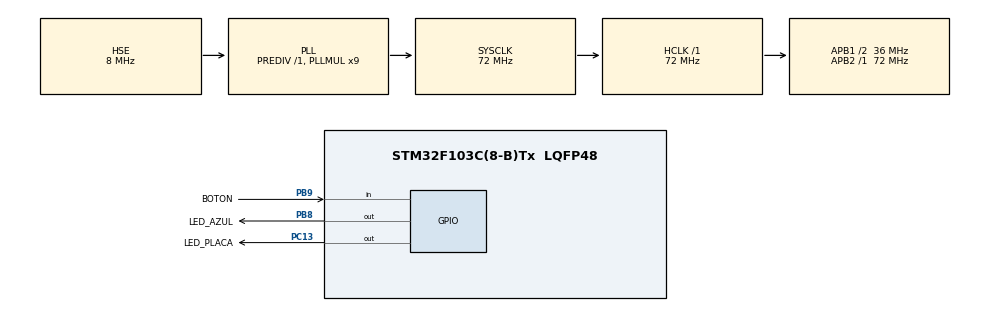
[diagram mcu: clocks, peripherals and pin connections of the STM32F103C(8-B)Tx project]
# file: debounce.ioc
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Mcu.Family=STM32F1
Mcu.Name=STM32F103C(8-B)Tx
Mcu.Package=LQFP48
NVIC.PriorityGroup=NVIC_PRIORITYGROUP_4
PA13.Mode=Serial_Wire
PA13.Signal=SYS_JTMS-SWDIO
PA14.Mode=Serial_Wire
PA14.Signal=SYS_JTCK-SWCLK
PB8.GPIO_Label=LED_AZUL
PB8.Signal=GPIO_Output
PB9.GPIO_Label=BOTON
PB9.GPIO_PuPd=GPIO_PULLUP
PB9.Signal=GPIO_Input
PC13-TAMPER-RTC.GPIO_Label=LED_PLACA
PC13-TAMPER-RTC.Signal=GPIO_Output
PD0-OSC_IN.Mode=HSE-External-Oscillator
PD0-OSC_IN.Signal=RCC_OSC_IN
PD1-OSC_OUT.Mode=HSE-External-Oscillator
PD1-OSC_OUT.Signal=RCC_OSC_OUT
ProjectManager.HeapSize=0x200
ProjectManager.StackSize=0x400
ProjectManager.TargetToolchain=STM32CubeIDE
RCC.AHBFreq_Value=72000000
RCC.APB1CLKDivider=RCC_HCLK_DIV2
RCC.APB1Freq_Value=36000000
RCC.APB1TimFreq_Value=72000000
RCC.APB2Freq_Value=72000000
RCC.APB2TimFreq_Value=72000000
RCC.HCLKFreq_Value=72000000
RCC.PLLMUL=RCC_PLL_MUL9
RCC.PLLSourceVirtual=RCC_PLLSOURCE_HSE
RCC.SYSCLKFreq_VALUE=72000000
RCC.SYSCLKSource=RCC_SYSCLKSOURCE_PLLCLK
RCC.USBFreq_Value=72000000
board=custom

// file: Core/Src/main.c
/* USER CODE BEGIN Header */
/**
  ******************************************************************************
  * @file           : main.c
  * @brief          : Main program body
  ******************************************************************************
  * @attention
  *
  * Copyright (c) 2022 STMicroelectronics.
  * All rights reserved.
  *
  * This software is licensed under terms that can be found in the LICENSE file
  * in the root directory of this software component.
  * If no LICENSE file comes with this software, it is provided AS-IS.
  *
  ******************************************************************************
  */
/* USER CODE END Header */
#include "main.h"

/* USER CODE BEGIN Includes */
#include "arrebote.h"
/* USER CODE END Includes */

/* USER CODE BEGIN PD */
#define TIC_LED					(125)
#define TIC_ANTIRREBOTE			(1)
#define PULSADOR_DEBOUNCE		(20)
#define PULSADOR_ESTADO_ACTIVO	(1)
/* USER CODE END PD */

void SystemClock_Config(void);
static void MX_GPIO_Init(void);

int main(void)
{
  /* USER CODE BEGIN 1 */
	uint32_t tics_led;
	uint32_t tics_antirrebote;
	arrebote debounce_pulsador;
  /* USER CODE END 1 */

  /* MCU Configuration--------------------------------------------------------*/

  /* Reset of all peripherals, Initializes the Flash interface and the Systick. */
  HAL_Init();

  /* Configure the system clock */
  SystemClock_Config();

  /* Initialize all configured peripherals */
  MX_GPIO_Init();
  /* USER CODE BEGIN 2 */
  inicializar_arrebote(&debounce_pulsador, PULSADOR_ESTADO_ACTIVO, PULSADOR_DEBOUNCE);
  tics_led = HAL_GetTick();
  tics_antirrebote = HAL_GetTick();

  /* USER CODE END 2 */

  /* Infinite loop */
  while (1)
  {

    /* USER CODE BEGIN 3 */
	  if((HAL_GetTick()-tics_led)>=TIC_LED)
	  {
		  tics_led = HAL_GetTick();
		  HAL_GPIO_TogglePin(LED_PLACA_GPIO_Port, LED_PLACA_Pin);

	  }

	  if((HAL_GetTick()-tics_antirrebote)>=TIC_ANTIRREBOTE)
	  	  {
	  		  tics_antirrebote = HAL_GetTick();
	  		  chequear_arrebote(&debounce_pulsador, HAL_GPIO_ReadPin(BOTON_GPIO_Port, BOTON_Pin));
	  		  if(hay_flanco_arrebote(&debounce_pulsador))
	  		  {
	  			  HAL_GPIO_TogglePin(LED_AZUL_GPIO_Port, LED_AZUL_Pin);
	  		  }
	  	  }

  }
  /* USER CODE END 3 */
}

void SystemClock_Config(void)
{
  RCC_OscInitTypeDef RCC_OscInitStruct = {0};
  RCC_ClkInitTypeDef RCC_ClkInitStruct = {0};

  /** Initializes the RCC Oscillators according to the specified parameters
  * in the RCC_OscInitTypeDef structure.
  */
  RCC_OscInitStruct.OscillatorType = RCC_OSCILLATORTYPE_HSE;
  RCC_OscInitStruct.HSEState = RCC_HSE_ON;
  RCC_OscInitStruct.HSEPredivValue = RCC_HSE_PREDIV_DIV1;
  RCC_OscInitStruct.HSIState = RCC_HSI_ON;
  RCC_OscInitStruct.PLL.PLLState = RCC_PLL_ON;
  RCC_OscInitStruct.PLL.PLLSource = RCC_PLLSOURCE_HSE;
  RCC_OscInitStruct.PLL.PLLMUL = RCC_PLL_MUL9;
  if (HAL_RCC_OscConfig(&RCC_OscInitStruct) != HAL_OK)
  {
    Error_Handler();
  }
  /** Initializes the CPU, AHB and APB buses clocks
  */
  RCC_ClkInitStruct.ClockType = RCC_CLOCKTYPE_HCLK|RCC_CLOCKTYPE_SYSCLK
                              |RCC_CLOCKTYPE_PCLK1|RCC_CLOCKTYPE_PCLK2;
  RCC_ClkInitStruct.SYSCLKSource = RCC_SYSCLKSOURCE_PLLCLK;
  RCC_ClkInitStruct.AHBCLKDivider = RCC_SYSCLK_DIV1;
  RCC_ClkInitStruct.APB1CLKDivider = RCC_HCLK_DIV2;
  RCC_ClkInitStruct.APB2CLKDivider = RCC_HCLK_DIV1;

  if (HAL_RCC_ClockConfig(&RCC_ClkInitStruct, FLASH_LATENCY_2) != HAL_OK)
  {
    Error_Handler();
  }
}

static void MX_GPIO_Init(void)
{
  GPIO_InitTypeDef GPIO_InitStruct = {0};

  /* GPIO Ports Clock Enable */
  __HAL_RCC_GPIOC_CLK_ENABLE();
  __HAL_RCC_GPIOD_CLK_ENABLE();
  __HAL_RCC_GPIOA_CLK_ENABLE();
  __HAL_RCC_GPIOB_CLK_ENABLE();

  /*Configure GPIO pin Output Level */
  HAL_GPIO_WritePin(LED_PLACA_GPIO_Port, LED_PLACA_Pin, GPIO_PIN_RESET);

  /*Configure GPIO pin Output Level */
  HAL_GPIO_WritePin(LED_AZUL_GPIO_Port, LED_AZUL_Pin, GPIO_PIN_RESET);

  /*Configure GPIO pin : LED_PLACA_Pin */
  GPIO_InitStruct.Pin = LED_PLACA_Pin;
  GPIO_InitStruct.Mode = GPIO_MODE_OUTPUT_PP;
  GPIO_InitStruct.Pull = GPIO_NOPULL;
  GPIO_InitStruct.Speed = GPIO_SPEED_FREQ_LOW;
  HAL_GPIO_Init(LED_PLACA_GPIO_Port, &GPIO_InitStruct);

  /*Configure GPIO pin : LED_AZUL_Pin */
  GPIO_InitStruct.Pin = LED_AZUL_Pin;
  GPIO_InitStruct.Mode = GPIO_MODE_OUTPUT_PP;
  GPIO_InitStruct.Pull = GPIO_NOPULL;
  GPIO_InitStruct.Speed = GPIO_SPEED_FREQ_LOW;
  HAL_GPIO_Init(LED_AZUL_GPIO_Port, &GPIO_InitStruct);

  /*Configure GPIO pin : BOTON_Pin */
  GPIO_InitStruct.Pin = BOTON_Pin;
  GPIO_InitStruct.Mode = GPIO_MODE_INPUT;
  GPIO_InitStruct.Pull = GPIO_PULLUP;
  HAL_GPIO_Init(BOTON_GPIO_Port, &GPIO_InitStruct);

}

void Error_Handler(void)
{
  __disable_irq();
  while (1)
  {
  }
}
